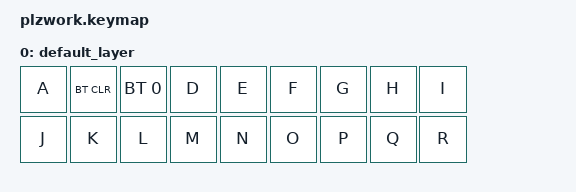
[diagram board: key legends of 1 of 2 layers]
#include <behaviors.dtsi>
#include <dt-bindings/zmk/keys.h>
#include <dt-bindings/zmk/bt.h>

/ {
    keymap {
        compatible = "zmk,keymap";

        default_layer {
            bindings = <
                &kp A &bt BT_CLR &bt BT_SEL 0 &kp D &kp E &kp F &kp G &kp H &kp I
                &kp J &kp K &kp L &kp M &kp N &kp O &kp P &kp Q &kp R
            >;
        };

        bt_layer {
            bindings = <
                &none   &none   &bootloader
                &none   &none   &bt BT_CLR
                &bt BT_SEL 0   &none   &none
            >;
        };

    };
};
